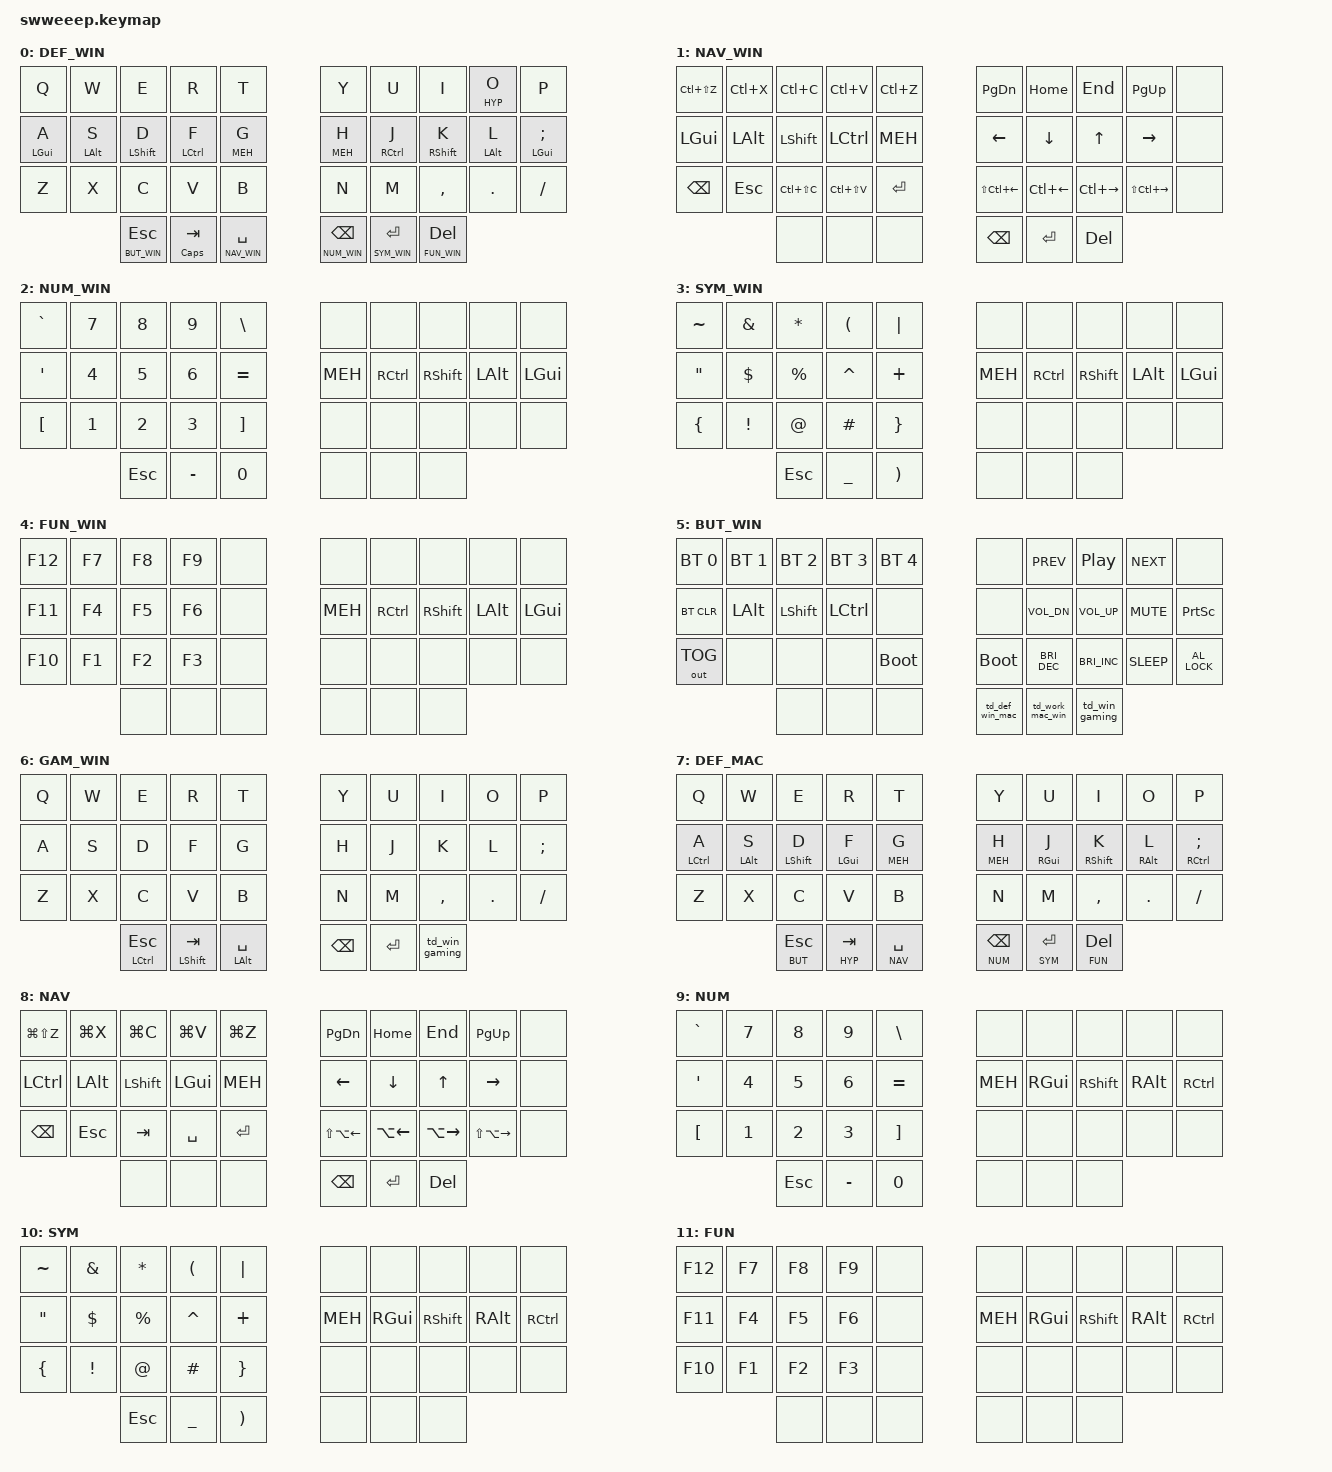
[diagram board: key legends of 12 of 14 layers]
#include <behaviors.dtsi>
#include <dt-bindings/zmk/keys.h>
#include <dt-bindings/zmk/bt.h>
#include <dt-bindings/zmk/outputs.h>
#include <dt-bindings/zmk/ext_power.h>

#define DEF_WIN 0
#define NAV_WIN 1
#define NUM_WIN 2
#define SYM_WIN 3
#define FUN_WIN 4
#define BUT_WIN 5
#define GAM_WIN 6
#define DEF_MAC 7
#define NAV 8
#define NUM 9
#define SYM 10
#define FUN 11
#define BUT 12
#define GAM 13

// Timing constants and Hyper/Meh keys
#define HYP LC(LA(LS(LGUI)))
#define MEH LC(LA(LSHFT))
#define COMBO_TIMEOUT 25
#define COMBO_PRIOR_IDLE 100
#define HM_PRIOR_IDLE 75
#define TAP_DANCE_TAPPING_TERM 250

// Caps word will continue to remain active after these keys
&caps_word {
    continue-list = <UNDERSCORE MINUS LS(MINUS) UP DOWN LEFT RIGHT BSPC DEL>;
};

/ {

    behaviors {

        // Homerow Mods allowing use of modifiers on the home row
        hm: homerow_mods {
            compatible = "zmk,behavior-hold-tap";
            label = "homerow_mods";
            #binding-cells = <2>;
            tapping-term-ms = <175>;
            quick_tap_ms = <200>;
            flavor = "tap-preferred";
            bindings = <&kp>, <&kp>;
        };

        // Layers that are activated when holding a thumb row key
        trl: thumb_row_layer {
            compatible = "zmk,behavior-hold-tap";
            label = "thumb_row_layer";
            #binding-cells = <2>;
            tapping-term-ms = <200>;
            quick-tap-ms = <200>;
            flavor = "tap-preferred";
            bindings = <&mo>, <&kp>;
        };

        // Tap-dance allowing easy switch between work laptop, mac and windows
        td_work_mac_win: tap_dance_work_mac_win {
            compatible = "zmk,behavior-tap-dance";
            label = "tap_dance_work_mac_win";
            #binding-cells = <0>;
            tapping-term-ms = <TAP_DANCE_TAPPING_TERM>;
            bindings = <&switch_to_work>, <&switch_to_mac>, <&switch_to_win>;
        };

        // Tap-dance allowing easy switch between mac default layer, gaming and sudoku layer
        td_mac_gaming: tap_dance_mac_gaming {
            compatible = "zmk,behavior-tap-dance";
            label = "tap_dance_mac_gaming";
            #binding-cells = <0>;
            tapping-term-ms = <TAP_DANCE_TAPPING_TERM>;
            bindings = <&to DEF_MAC>, <&to GAM>;
        };

        // Tap-dance allowing easy switch between windows default layer and gaming layer
        td_win_gaming: tap_dance_win_gaming {
            compatible = "zmk,behavior-tap-dance";
            label = "tap_dance_win_gaming";
            #binding-cells = <0>;
            tapping-term-ms = <TAP_DANCE_TAPPING_TERM>;
            bindings = <&to DEF_WIN>, <&to GAM_WIN>;
        };

        // Tap-dance allowing easy switch between windows default layer and mac default layer
        td_def_win_mac: tap_dance_def_win_mac {
            compatible = "zmk,behavior-tap-dance";
            label = "tap_dance_def_win_mac";
            #binding-cells = <0>;
            tapping-term-ms = <TAP_DANCE_TAPPING_TERM>;
            bindings = <&to DEF_WIN>, <&to DEF_MAC>;
        };

    };

    macros {

        // Macro to select mac bluetooth profile and switch to default mac layer
        switch_to_mac: switch_to_mac {
            label = "Macro_switch_to_mac";
            compatible = "zmk,behavior-macro";
            #binding-cells = <0>;
            bindings = <&macro_tap &bt BT_SEL 0> , <&macro_tap &to DEF_MAC> ;
        };

        // Macro to select work laptop bluetooth profile and switch to default windows layer
        switch_to_work: switch_to_work {
            label = "Macro_switch_to_work";
            compatible = "zmk,behavior-macro";
            #binding-cells = <0>;
            bindings = <&macro_tap &bt BT_SEL 2> , <&macro_tap &to DEF_WIN> ;
        };

        // Macro to select windows bluetooth profile and switch to default windows layer
        switch_to_win: switch_to_win {
            label = "Macro_switch_to_win";
            compatible = "zmk,behavior-macro";
            #binding-cells = <0>;
            bindings = <&macro_tap &bt BT_SEL 4> , <&macro_tap &to DEF_WIN> ;
        };

    };

    combos {

        compatible = "zmk,combos";

        // Simultaneous D+K : Turn on caps_word
        combo_caps_word {
            timeout-ms = <COMBO_TIMEOUT>;
            key-positions = <12 17>;
            layers = <DEF_MAC DEF_WIN>;
			slow-release;
            bindings = <&caps_word>;
        };

        // Simultaneous D+F+J+K : Toggle Caps Lock
        combo_caps_lock {
            timeout-ms = <COMBO_TIMEOUT>;
            key-positions = <12 13 16 17>;
            layers = <DEF_MAC DEF_WIN>;
			slow-release;
            bindings = <&kp CAPS>;
        };

        // Simultaneous C+V : Switch to previous app on mac
        combo_previous_app_mac {
            timeout-ms = <COMBO_TIMEOUT>;
            require-prior-idle-ms = <COMBO_PRIOR_IDLE>;
            key-positions = <22 23>;
            layers = <DEF_MAC>;
			slow-release;
            bindings = <&kp LG(TAB)>;
        };

        // Simultaneous X+C : Switch to previous window of current app on mac
        combo_previous_window_mac {
            timeout-ms = <COMBO_TIMEOUT>;
            require-prior-idle-ms = <COMBO_PRIOR_IDLE>;
            key-positions = <21 22>;
            layers = <DEF_MAC>;
			slow-release;
            bindings = <&kp LG(GRAVE)>;
        };

        // Simultaneous C+V : Switch to previous app on windows
        combo_previous_app_windows {
            timeout-ms = <COMBO_TIMEOUT>;
            require-prior-idle-ms = <COMBO_PRIOR_IDLE>;
            key-positions = <22 23>;
            layers = <DEF_WIN>;
			slow-release;
            bindings = <&kp LA(TAB)>;
        };

        // Simultaneous X+C : Switch to previous window of current app on windows
        combo_previous_window_windows {
            timeout-ms = <COMBO_TIMEOUT>;
            require-prior-idle-ms = <COMBO_PRIOR_IDLE>;
            key-positions = <21 22>;
            layers = <DEF_WIN>;
			slow-release;
            bindings = <&kp LA(GRAVE)>;
        };

        // Simultaneous W+E : Type (
        combo_left_parenthesis {
            timeout-ms = <COMBO_TIMEOUT>;
            require-prior-idle-ms = <COMBO_PRIOR_IDLE>;
            key-positions = <1 2>;
            layers = <DEF_MAC DEF_WIN>;
			slow-release;
            bindings = <&kp LPAR>;
        };

        // Simultaneous E+R : Type )
        combo_right_parenthesis {
            timeout-ms = <COMBO_TIMEOUT>;
            require-prior-idle-ms = <COMBO_PRIOR_IDLE>;
            key-positions = <2 3>;
            layers = <DEF_MAC DEF_WIN>;
			slow-release;
            bindings = <&kp RPAR>;
        };

        // Simultaneous U+I : Type {
        combo_left_brace {
            timeout-ms = <COMBO_TIMEOUT>;
            require-prior-idle-ms = <COMBO_PRIOR_IDLE>;
            key-positions = <6 7>;
            layers = <DEF_MAC DEF_WIN>;
			slow-release;
            bindings = <&kp LBRC>;
        };

        // Simultaneous I+O : Type }
        combo_right_brace {
            timeout-ms = <COMBO_TIMEOUT>;
            require-prior-idle-ms = <COMBO_PRIOR_IDLE>;
            key-positions = <7 8>;
            layers = <DEF_MAC DEF_WIN>;
			slow-release;
            bindings = <&kp RBRC>;
        };

        // Simultaneous M+, : Type [
        combo_left_bracket {
            timeout-ms = <COMBO_TIMEOUT>;
            require-prior-idle-ms = <COMBO_PRIOR_IDLE>;
            key-positions = <26 27>;
            layers = <DEF_MAC DEF_WIN>;
			slow-release;
            bindings = <&kp LBKT>;
        };

        // Simultaneous ,+. : Type ]
        combo_right_bracket {
            timeout-ms = <COMBO_TIMEOUT>;
            require-prior-idle-ms = <COMBO_PRIOR_IDLE>;
            key-positions = <27 28>;
            layers = <DEF_MAC DEF_WIN>;
			slow-release;
            bindings = <&kp RBKT>;
        };

    };

    keymap {
        compatible = "zmk,keymap";

        win_default_layer {
            label = "DEF_WIN";
            bindings = <
//    ┌────────────┬────────────┬────────────┬──────────────────┬──────────────┐                                      ┌──────────────────┬──────────────────┬────────────┬────────────┬────────────┐
//    │     Q      │     W      │     E      │        R         │      T       │                                      │        Y         │        U         │     I      │ &hm HYP O  │     P      │
//    ├────────────┼────────────┼────────────┼──────────────────┼──────────────┤                                      ├──────────────────┼──────────────────┼────────────┼────────────┼────────────┤
//    │ &hm lgui A │ &hm lalt S │ &hm lsft D │    &hm lctl F    │  &hm MEH G   │                                      │    &hm MEH H     │    &hm rctl J    │ &hm rsft K │ &hm lalt L │ &hm lgui ; │
//    ├────────────┼────────────┼────────────┼──────────────────┼──────────────┤                                      ├──────────────────┼──────────────────┼────────────┼────────────┼────────────┤
//    │     Z      │     X      │     C      │        V         │      B       │                                      │        N         │        M         │     ,      │     .      │     /      │
//    └────────────┴────────────┴────────────┼──────────────────┼──────────────┼──────────────────┬───────────────────┼──────────────────┼──────────────────┼────────────┴────────────┴────────────┘
//                                           │ &trl BUT_WIN esc │ &hm caps tab │ &trl NAV_WIN spc │ &trl NUM_WIN bspc │ &trl SYM_WIN ent │ &trl FUN_WIN del │
//                                           └──────────────────┴──────────────┴──────────────────┴───────────────────┴──────────────────┴──────────────────┘
  &kp Q        &kp W        &kp E         &kp R              &kp T                                                   &kp Y              &kp U              &kp I         &hm HYP O    &kp P
  &hm LGUI A   &hm LALT S   &hm LSHFT D   &hm LCTRL F        &hm MEH G                                               &hm MEH H          &hm RCTRL J        &hm RSHFT K   &hm LALT L   &hm LGUI SEMI
  &kp Z        &kp X        &kp C         &kp V              &kp B                                                   &kp N              &kp M              &kp COMMA     &kp DOT      &kp FSLH
                                          &trl BUT_WIN ESC   &hm CAPS TAB   &trl NAV_WIN SPACE   &trl NUM_WIN BSPC   &trl SYM_WIN RET   &trl FUN_WIN DEL
            >;
        };

		win_navigation_layer {
            label = "NAV_WIN";
            bindings = <
//    ┌───────────────┬─────────┬───────────────┬───────────────┬─────────┐            ┌──────────────────┬────────────┬────────────┬──────────────────┬─────┐
//    │ lctl(lsft(Z)) │ lctl(X) │    lctl(C)    │    lctl(V)    │ lctl(Z) │            │       pgdn       │    home    │    end     │       pgup       │     │
//    ├───────────────┼─────────┼───────────────┼───────────────┼─────────┤            ├──────────────────┼────────────┼────────────┼──────────────────┼─────┤
//    │     lgui      │  lalt   │     lsft      │     lctl      │   MEH   │            │       left       │    down    │     up     │       rght       │     │
//    ├───────────────┼─────────┼───────────────┼───────────────┼─────────┤            ├──────────────────┼────────────┼────────────┼──────────────────┼─────┤
//    │     bspc      │   esc   │ lctl(lsft(C)) │ lctl(lsft(V)) │   ent   │            │ lsft(lctl(left)) │ lctl(left) │ lctl(rght) │ lsft(lctl(rght)) │     │
//    └───────────────┴─────────┴───────────────┼───────────────┼─────────┼─────┬──────┼──────────────────┼────────────┼────────────┴──────────────────┴─────┘
//                                              │               │         │     │ bspc │       ent        │    del     │
//                                              └───────────────┴─────────┴─────┴──────┴──────────────────┴────────────┘
  &kp LC(LS(Z))   &kp LC(X)   &kp LC(C)       &kp LC(V)       &kp LC(Z)                      &kp PG_DN          &kp HOME       &kp END         &kp PG_UP           &none
  &kp LGUI        &kp LALT    &kp LSHFT       &kp LCTRL       &kp MEH                        &kp LEFT           &kp DOWN       &kp UP          &kp RIGHT           &none
  &kp BSPC        &kp ESC     &kp LC(LS(C))   &kp LC(LS(V))   &kp RET                        &kp LS(LC(LEFT))   &kp LC(LEFT)   &kp LC(RIGHT)   &kp LS(LC(RIGHT))   &none
                                              &none           &none       &none   &kp BSPC   &kp RET            &kp DEL
            >;
        };

		win_number_layer {
            label = "NUM_WIN";
			bindings = <
//    ┌───┬───┬───┬─────┬───┐         ┌─────┬──────┬──────┬──────┬──────┐
//    │ ` │ 7 │ 8 │  9  │ \ │         │     │      │      │      │      │
//    ├───┼───┼───┼─────┼───┤         ├─────┼──────┼──────┼──────┼──────┤
//    │ ' │ 4 │ 5 │  6  │ = │         │ MEH │ rctl │ rsft │ lalt │ lgui │
//    ├───┼───┼───┼─────┼───┤         ├─────┼──────┼──────┼──────┼──────┤
//    │ [ │ 1 │ 2 │  3  │ ] │         │     │      │      │      │      │
//    └───┴───┴───┼─────┼───┼───┬─────┼─────┼──────┼──────┴──────┴──────┘
//                │ esc │ - │ 0 │     │     │      │
//                └─────┴───┴───┴─────┴─────┴──────┘
  &kp GRAVE   &kp N7   &kp N8   &kp N9    &kp BSLH                     &none     &none       &none       &none      &none
  &kp SQT     &kp N4   &kp N5   &kp N6    &kp EQUAL                    &kp MEH   &kp RCTRL   &kp RSHFT   &kp LALT   &kp LGUI
  &kp LBKT    &kp N1   &kp N2   &kp N3    &kp RBKT                     &none     &none       &none       &none      &none
                                &kp ESC   &kp MINUS   &kp N0   &none   &none     &none
			>;
		};

		win_symbol_layer {
            label = "SYM_WIN";
            bindings = <
//    ┌───┬───┬───┬─────┬───┐         ┌─────┬──────┬──────┬──────┬──────┐
//    │ ~ │ & │ * │  (  │ | │         │     │      │      │      │      │
//    ├───┼───┼───┼─────┼───┤         ├─────┼──────┼──────┼──────┼──────┤
//    │ " │ $ │ % │  ^  │ + │         │ MEH │ rctl │ rsft │ lalt │ lgui │
//    ├───┼───┼───┼─────┼───┤         ├─────┼──────┼──────┼──────┼──────┤
//    │ { │ ! │ @ │  #  │ } │         │     │      │      │      │      │
//    └───┴───┴───┼─────┼───┼───┬─────┼─────┼──────┼──────┴──────┴──────┘
//                │ esc │ _ │ ) │     │     │      │
//                └─────┴───┴───┴─────┴─────┴──────┘
  &kp TILDE   &kp AMPS     &kp ASTRK   &kp LPAR    &kp PIPE                       &none     &none       &none       &none      &none
  &kp DQT     &kp DOLLAR   &kp PRCNT   &kp CARET   &kp PLUS                       &kp MEH   &kp RCTRL   &kp RSHFT   &kp LALT   &kp LGUI
  &kp LBRC    &kp EXCL     &kp AT      &kp HASH    &kp RBRC                       &none     &none       &none       &none      &none
                                       &kp ESC     &kp UNDER   &kp RPAR   &none   &none     &none
            >;
        };
			
		win_function_layer {
            label = "FUN_WIN";
			bindings = <
//    ┌─────┬────┬────┬─────┬─────┐           ┌─────┬──────┬──────┬──────┬──────┐
//    │ f12 │ f7 │ f8 │ f9  │     │           │     │      │      │      │      │
//    ├─────┼────┼────┼─────┼─────┤           ├─────┼──────┼──────┼──────┼──────┤
//    │ f11 │ f4 │ f5 │ f6  │     │           │ MEH │ rctl │ rsft │ lalt │ lgui │
//    ├─────┼────┼────┼─────┼─────┤           ├─────┼──────┼──────┼──────┼──────┤
//    │ f10 │ f1 │ f2 │ f3  │     │           │     │      │      │      │      │
//    └─────┴────┴────┼─────┼─────┼─────┬─────┼─────┼──────┼──────┴──────┴──────┘
//                    │     │     │     │     │     │      │
//                    └─────┴─────┴─────┴─────┴─────┴──────┘
  &kp F12   &kp F7   &kp F8   &kp F9   &none                   &none     &none       &none       &none      &none
  &kp F11   &kp F4   &kp F5   &kp F6   &none                   &kp MEH   &kp RCTRL   &kp RSHFT   &kp LALT   &kp LGUI
  &kp F10   &kp F1   &kp F2   &kp F3   &none                   &none     &none       &none       &none      &none
                              &none    &none   &none   &none   &none     &none
			>;
		};

		win_button_layer {
            label = "BUT_WIN";
			bindings = <
//    ┌──────────┬──────────┬──────────┬──────────┬──────────┐                       ┌──────────────────┬────────────────┬──────┬───────┬───────────┐
//    │ bt_sel 0 │ bt_sel 1 │ bt_sel 2 │ bt_sel 3 │ bt_sel 4 │                       │                  │      prev      │ play │ next  │           │
//    ├──────────┼──────────┼──────────┼──────────┼──────────┤                       ├──────────────────┼────────────────┼──────┼───────┼───────────┤
//    │  bt_clr  │   lalt   │   lsft   │   lctl   │          │                       │                  │      vold      │ volu │ mute  │   pscr    │
//    ├──────────┼──────────┼──────────┼──────────┼──────────┤                       ├──────────────────┼────────────────┼──────┼───────┼───────────┤
//    │ out_ tog │          │          │          │   boot   │                       │       boot       │      bri-      │ bri+ │ sleep │ term_lock │
//    └──────────┴──────────┴──────────┼──────────┼──────────┼─────┬─────────────────┼──────────────────┼────────────────┼──────┴───────┴───────────┘
//                                     │          │          │     │ &td_def_win_mac │ &td_work_mac_win │ &td_win_gaming │
//                                     └──────────┴──────────┴─────┴─────────────────┴──────────────────┴────────────────┘
  &bt BT_SEL 0   &bt BT_SEL 1   &bt BT_SEL 2   &bt BT_SEL 3   &bt BT_SEL 4                             &none              &kp C_PREV       &kp C_PLAY_PAUSE   &kp C_NEXT    &none
  &bt BT_CLR     &kp LALT       &kp LSHFT      &kp LCTRL      &none                                    &none              &kp C_VOL_DN     &kp C_VOL_UP       &kp C_MUTE    &kp PSCRN
  &out OUT_TOG   &none          &none          &none          &bootloader                              &bootloader        &kp C_BRI_DEC    &kp C_BRI_INC      &kp C_SLEEP   &kp C_AL_LOCK
                                               &none          &none          &none   &td_def_win_mac   &td_work_mac_win   &td_win_gaming
			>;
		};

		win_gaming_layer {
            label = "GAM_WIN";
			bindings = <
//    ┌───┬───┬───┬──────────────┬──────────────┐                     ┌─────┬────────────────┬───┬───┬───┐
//    │ Q │ W │ E │      R       │      T       │                     │  Y  │       U        │ I │ O │ P │
//    ├───┼───┼───┼──────────────┼──────────────┤                     ├─────┼────────────────┼───┼───┼───┤
//    │ A │ S │ D │      F       │      G       │                     │  H  │       J        │ K │ L │ ; │
//    ├───┼───┼───┼──────────────┼──────────────┤                     ├─────┼────────────────┼───┼───┼───┤
//    │ Z │ X │ C │      V       │      B       │                     │  N  │       M        │ , │ . │ / │
//    └───┴───┴───┼──────────────┼──────────────┼──────────────┬──────┼─────┼────────────────┼───┴───┴───┘
//                │ &hm lctl esc │ &hm lsft tab │ &hm lalt spc │ bspc │ ent │ &td_win_gaming │
//                └──────────────┴──────────────┴──────────────┴──────┴─────┴────────────────┘
  &kp Q   &kp W   &kp E   &kp R           &kp T                                       &kp Y     &kp U            &kp I       &kp O     &kp P
  &kp A   &kp S   &kp D   &kp F           &kp G                                       &kp H     &kp J            &kp K       &kp L     &kp SEMI
  &kp Z   &kp X   &kp C   &kp V           &kp B                                       &kp N     &kp M            &kp COMMA   &kp DOT   &kp FSLH
                          &hm LCTRL ESC   &hm LSHFT TAB   &hm LALT SPACE   &kp BSPC   &kp RET   &td_win_gaming
			>;
		};

        mac_default_layer {
            label = "DEF_MAC";
            bindings = <
//    ┌────────────┬────────────┬────────────┬──────────────┬─────────────┐                              ┌──────────────┬──────────────┬────────────┬────────────┬────────────┐
//    │     Q      │     W      │     E      │      R       │      T      │                              │      Y       │      U       │     I      │     O      │     P      │
//    ├────────────┼────────────┼────────────┼──────────────┼─────────────┤                              ├──────────────┼──────────────┼────────────┼────────────┼────────────┤
//    │ &hm lctl A │ &hm lalt S │ &hm lsft D │  &hm lgui F  │  &hm MEH G  │                              │  &hm MEH H   │  &hm rgui J  │ &hm rsft K │ &hm ralt L │ &hm rctl ; │
//    ├────────────┼────────────┼────────────┼──────────────┼─────────────┤                              ├──────────────┼──────────────┼────────────┼────────────┼────────────┤
//    │     Z      │     X      │     C      │      V       │      B      │                              │      N       │      M       │     ,      │     .      │     /      │
//    └────────────┴────────────┴────────────┼──────────────┼─────────────┼──────────────┬───────────────┼──────────────┼──────────────┼────────────┴────────────┴────────────┘
//                                           │ &trl BUT esc │ &hm HYP tab │ &trl NAV spc │ &trl NUM bspc │ &trl SYM ent │ &trl FUN del │
//                                           └──────────────┴─────────────┴──────────────┴───────────────┴──────────────┴──────────────┘
  &kp Q         &kp W        &kp E         &kp R          &kp T                                          &kp Y          &kp U          &kp I         &kp O        &kp P
  &hm LCTRL A   &hm LALT S   &hm LSHFT D   &hm LGUI F     &hm MEH G                                      &hm MEH H      &hm RGUI J     &hm RSHFT K   &hm RALT L   &hm RCTRL SEMI
  &kp Z         &kp X        &kp C         &kp V          &kp B                                          &kp N          &kp M          &kp COMMA     &kp DOT      &kp FSLH
                                           &trl BUT ESC   &hm HYP TAB   &trl NAV SPACE   &trl NUM BSPC   &trl SYM RET   &trl FUN DEL
            >;
        };

		mac_navigation_layer {
            label = "NAV";
            bindings = <
//    ┌───────────────┬─────────┬─────────┬─────────┬─────────┐            ┌──────────────────┬────────────┬────────────┬──────────────────┬─────┐
//    │ lgui(lsft(Z)) │ lgui(X) │ lgui(C) │ lgui(V) │ lgui(Z) │            │       pgdn       │    home    │    end     │       pgup       │     │
//    ├───────────────┼─────────┼─────────┼─────────┼─────────┤            ├──────────────────┼────────────┼────────────┼──────────────────┼─────┤
//    │     lctl      │  lalt   │  lsft   │  lgui   │   MEH   │            │       left       │    down    │     up     │       rght       │     │
//    ├───────────────┼─────────┼─────────┼─────────┼─────────┤            ├──────────────────┼────────────┼────────────┼──────────────────┼─────┤
//    │     bspc      │   esc   │   tab   │   spc   │   ent   │            │ lsft(lalt(left)) │ lalt(left) │ lalt(rght) │ lsft(lalt(rght)) │     │
//    └───────────────┴─────────┴─────────┼─────────┼─────────┼─────┬──────┼──────────────────┼────────────┼────────────┴──────────────────┴─────┘
//                                        │         │         │     │ bspc │       ent        │    del     │
//                                        └─────────┴─────────┴─────┴──────┴──────────────────┴────────────┘
  &kp LG(LS(Z))   &kp LG(X)   &kp LG(C)   &kp LG(V)   &kp LG(Z)                      &kp PG_DN          &kp HOME       &kp END         &kp PG_UP           &none
  &kp LCTRL       &kp LALT    &kp LSHFT   &kp LGUI    &kp MEH                        &kp LEFT           &kp DOWN       &kp UP          &kp RIGHT           &none
  &kp BSPC        &kp ESC     &kp TAB     &kp SPACE   &kp RET                        &kp LS(LA(LEFT))   &kp LA(LEFT)   &kp LA(RIGHT)   &kp LS(LA(RIGHT))   &none
                                          &none       &none       &none   &kp BSPC   &kp RET            &kp DEL
            >;
        };

		mac_number_layer {
            label = "NUM";
			bindings = <
//    ┌───┬───┬───┬─────┬───┐         ┌─────┬──────┬──────┬──────┬──────┐
//    │ ` │ 7 │ 8 │  9  │ \ │         │     │      │      │      │      │
//    ├───┼───┼───┼─────┼───┤         ├─────┼──────┼──────┼──────┼──────┤
//    │ ' │ 4 │ 5 │  6  │ = │         │ MEH │ rgui │ rsft │ ralt │ rctl │
//    ├───┼───┼───┼─────┼───┤         ├─────┼──────┼──────┼──────┼──────┤
//    │ [ │ 1 │ 2 │  3  │ ] │         │     │      │      │      │      │
//    └───┴───┴───┼─────┼───┼───┬─────┼─────┼──────┼──────┴──────┴──────┘
//                │ esc │ - │ 0 │     │     │      │
//                └─────┴───┴───┴─────┴─────┴──────┘
  &kp GRAVE   &kp N7   &kp N8   &kp N9    &kp BSLH                     &none     &none      &none       &none      &none
  &kp SQT     &kp N4   &kp N5   &kp N6    &kp EQUAL                    &kp MEH   &kp RGUI   &kp RSHFT   &kp RALT   &kp RCTRL
  &kp LBKT    &kp N1   &kp N2   &kp N3    &kp RBKT                     &none     &none      &none       &none      &none
                                &kp ESC   &kp MINUS   &kp N0   &none   &none     &none
			>;
		};

		mac_symbol_layer {
            label = "SYM";
            bindings = <
//    ┌───┬───┬───┬─────┬───┐         ┌─────┬──────┬──────┬──────┬──────┐
//    │ ~ │ & │ * │  (  │ | │         │     │      │      │      │      │
//    ├───┼───┼───┼─────┼───┤         ├─────┼──────┼──────┼──────┼──────┤
//    │ " │ $ │ % │  ^  │ + │         │ MEH │ rgui │ rsft │ ralt │ rctl │
//    ├───┼───┼───┼─────┼───┤         ├─────┼──────┼──────┼──────┼──────┤
//    │ { │ ! │ @ │  #  │ } │         │     │      │      │      │      │
//    └───┴───┴───┼─────┼───┼───┬─────┼─────┼──────┼──────┴──────┴──────┘
//                │ esc │ _ │ ) │     │     │      │
//                └─────┴───┴───┴─────┴─────┴──────┘
  &kp TILDE   &kp AMPS     &kp ASTRK   &kp LPAR    &kp PIPE                       &none     &none      &none       &none      &none
  &kp DQT     &kp DOLLAR   &kp PRCNT   &kp CARET   &kp PLUS                       &kp MEH   &kp RGUI   &kp RSHFT   &kp RALT   &kp RCTRL
  &kp LBRC    &kp EXCL     &kp AT      &kp HASH    &kp RBRC                       &none     &none      &none       &none      &none
                                       &kp ESC     &kp UNDER   &kp RPAR   &none   &none     &none
            >;
        };
			
		mac_function_layer {
            label = "FUN";
			bindings = <
//    ┌─────┬────┬────┬─────┬─────┐           ┌─────┬──────┬──────┬──────┬──────┐
//    │ f12 │ f7 │ f8 │ f9  │     │           │     │      │      │      │      │
//    ├─────┼────┼────┼─────┼─────┤           ├─────┼──────┼──────┼──────┼──────┤
//    │ f11 │ f4 │ f5 │ f6  │     │           │ MEH │ rgui │ rsft │ ralt │ rctl │
//    ├─────┼────┼────┼─────┼─────┤           ├─────┼──────┼──────┼──────┼──────┤
//    │ f10 │ f1 │ f2 │ f3  │     │           │     │      │      │      │      │
//    └─────┴────┴────┼─────┼─────┼─────┬─────┼─────┼──────┼──────┴──────┴──────┘
//                    │     │     │     │     │     │      │
//                    └─────┴─────┴─────┴─────┴─────┴──────┘
  &kp F12   &kp F7   &kp F8   &kp F9   &none                   &none     &none      &none       &none      &none
  &kp F11   &kp F4   &kp F5   &kp F6   &none                   &kp MEH   &kp RGUI   &kp RSHFT   &kp RALT   &kp RCTRL
  &kp F10   &kp F1   &kp F2   &kp F3   &none                   &none     &none      &none       &none      &none
                              &none    &none   &none   &none   &none     &none
			>;
		};

		mac_button_layer {
            label = "BUT";
			bindings = <
//    ┌──────────┬──────────┬──────────┬──────────┬──────────┐                       ┌──────────────────┬────────────────┬──────┬──────┬───────────┐
//    │ bt_sel 0 │ bt_sel 1 │ bt_sel 2 │ bt_sel 3 │ bt_sel 4 │                       │                  │      prev      │ play │ next │           │
//    ├──────────┼──────────┼──────────┼──────────┼──────────┤                       ├──────────────────┼────────────────┼──────┼──────┼───────────┤
//    │  bt_clr  │          │          │          │          │                       │                  │      vold      │ volu │ mute │           │
//    ├──────────┼──────────┼──────────┼──────────┼──────────┤                       ├──────────────────┼────────────────┼──────┼──────┼───────────┤
//    │ out_ tog │          │          │          │   boot   │                       │       boot       │      bri-      │ bri+ │ pwr  │ term_lock │
//    └──────────┴──────────┴──────────┼──────────┼──────────┼─────┬─────────────────┼──────────────────┼────────────────┼──────┴──────┴───────────┘
//                                     │          │          │     │ &td_def_win_mac │ &td_work_mac_win │ &td_mac_gaming │
//                                     └──────────┴──────────┴─────┴─────────────────┴──────────────────┴────────────────┘
  &bt BT_SEL 0   &bt BT_SEL 1   &bt BT_SEL 2   &bt BT_SEL 3   &bt BT_SEL 4                             &none              &kp C_PREV       &kp C_PLAY_PAUSE   &kp C_NEXT    &none
  &bt BT_CLR     &none          &none          &none          &none                                    &none              &kp C_VOL_DN     &kp C_VOL_UP       &kp C_MUTE    &none
  &out OUT_TOG   &none          &none          &none          &bootloader                              &bootloader        &kp C_BRI_DEC    &kp C_BRI_INC      &kp C_POWER   &kp C_AL_LOCK
                                               &none          &none          &none   &td_def_win_mac   &td_work_mac_win   &td_mac_gaming
			>;
		};

		mac_gaming_layer {
            label = "GAM";
			bindings = <
//    ┌───┬───┬───┬──────────────┬──────────────┐                     ┌─────┬────────────────┬───┬───┬───┐
//    │ Q │ W │ E │      R       │      T       │                     │  Y  │       U        │ I │ O │ P │
//    ├───┼───┼───┼──────────────┼──────────────┤                     ├─────┼────────────────┼───┼───┼───┤
//    │ A │ S │ D │      F       │      G       │                     │  H  │       J        │ K │ L │ ; │
//    ├───┼───┼───┼──────────────┼──────────────┤                     ├─────┼────────────────┼───┼───┼───┤
//    │ Z │ X │ C │      V       │      B       │                     │  N  │       M        │ , │ . │ / │
//    └───┴───┴───┼──────────────┼──────────────┼──────────────┬──────┼─────┼────────────────┼───┴───┴───┘
//                │ &hm lctl esc │ &hm lsft tab │ &hm lalt spc │ bspc │ ent │ &td_mac_gaming │
//                └──────────────┴──────────────┴──────────────┴──────┴─────┴────────────────┘
  &kp Q   &kp W   &kp E   &kp R           &kp T                                       &kp Y     &kp U            &kp I       &kp O     &kp P
  &kp A   &kp S   &kp D   &kp F           &kp G                                       &kp H     &kp J            &kp K       &kp L     &kp SEMI
  &kp Z   &kp X   &kp C   &kp V           &kp B                                       &kp N     &kp M            &kp COMMA   &kp DOT   &kp FSLH
                          &hm LCTRL ESC   &hm LSHFT TAB   &hm LALT SPACE   &kp BSPC   &kp RET   &td_mac_gaming
			>;
		};

    };

};
